AUTOSAR XML (schema 00053)
package /SoftwareComponents/ApplicationSWComponents
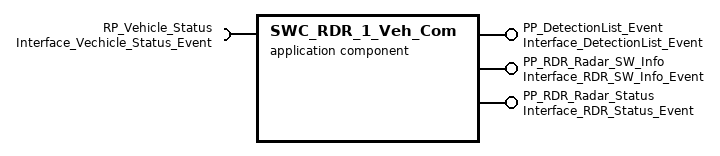
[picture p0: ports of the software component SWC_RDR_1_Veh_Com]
  application sw component type SWC_RDR_1_Veh_Com
    provide port PP_DetectionList_Event: nonqueued-sender-com-spec=DetectionList_Event, provided-interface=Interface_DetectionList_Event
    provide port PP_RDR_Radar_SW_Info: nonqueued-sender-com-spec=RDR_SW_Info, provided-interface=Interface_RDR_SW_Info_Event
    provide port PP_RDR_Radar_Status: nonqueued-sender-com-spec=RDR_Status, provided-interface=Interface_RDR_Status_Event
    require port RP_Vehicle_Status: nonqueued-receiver-com-spec=Vehicle_Status, required-interface=Interface_Vechicle_Status_Event
